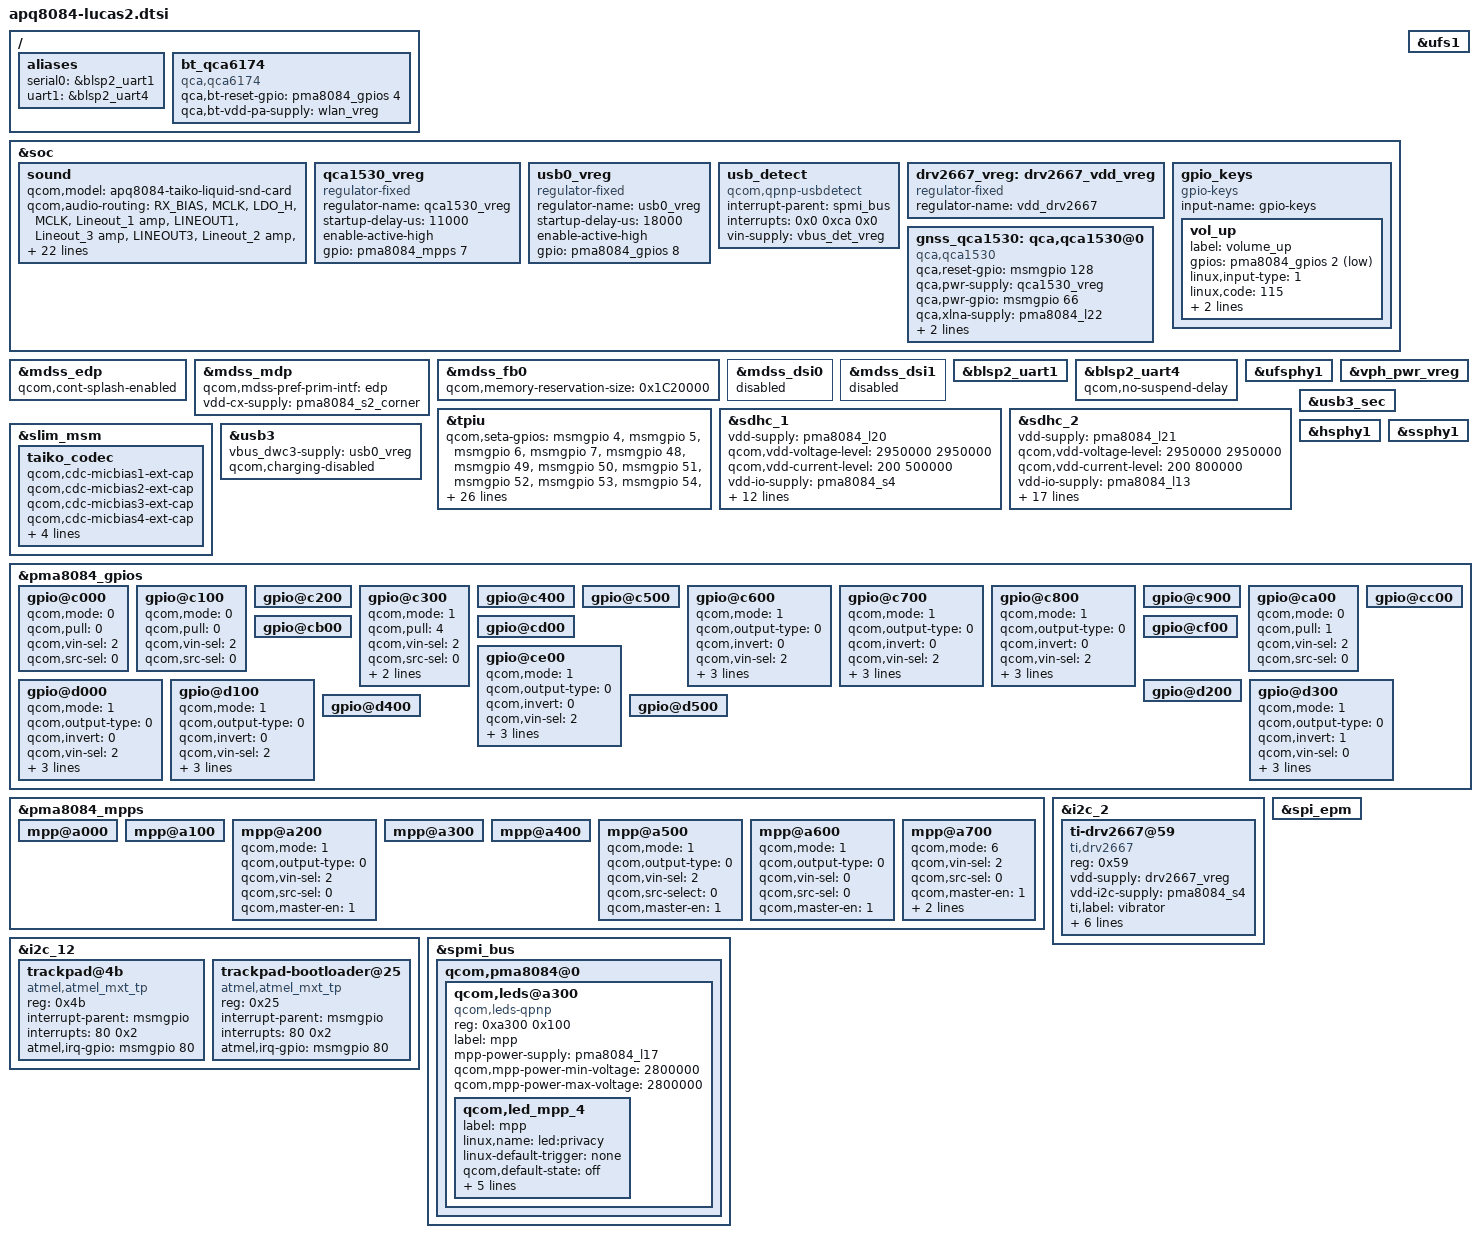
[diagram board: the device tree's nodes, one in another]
/* Copyright (c) 2014, The Linux Foundation. All rights reserved.
 *
 * This program is free software; you can redistribute it and/or modify
 * it under the terms of the GNU General Public License version 2 and
 * only version 2 as published by the Free Software Foundation.
 *
 * This program is distributed in the hope that it will be useful,
 * but WITHOUT ANY WARRANTY; without even the implied warranty of
 * MERCHANTABILITY or FITNESS FOR A PARTICULAR PURPOSE.  See the
 * GNU General Public License for more details.
 */

/ {
	aliases {
		serial0 = &blsp2_uart1;
		uart1 = &blsp2_uart4;
	};

	bt_qca6174 {
		compatible = "qca,qca6174";
		qca,bt-reset-gpio = <&pma8084_gpios 4 0>; /* BT_EN */
		qca,bt-vdd-pa-supply = <&wlan_vreg>;
	};
};

&soc {
	sound {
		qcom,model = "apq8084-taiko-liquid-snd-card";

		qcom,audio-routing =
			"RX_BIAS", "MCLK",
			"LDO_H", "MCLK",
			"Lineout_1 amp", "LINEOUT1",
			"Lineout_3 amp", "LINEOUT3",
			"Lineout_2 amp", "LINEOUT2",
			"Lineout_4 amp", "LINEOUT4",
			"SPK_ultrasound amp", "SPK_OUT",
			"AMIC1", "MIC BIAS3 External",
			"MIC BIAS3 External", "Analog Mic7",
			"AMIC2", "MIC BIAS2 External",
			"MIC BIAS2 External", "Headset Mic",
			"AMIC3", "MIC BIAS2 External",
			"MIC BIAS2 External", "ANCLeft Headset Mic",
			"AMIC4", "MIC BIAS2 External",
			"MIC BIAS2 External", "ANCRight Headset Mic",
			"DMIC1", "MIC BIAS4 External",
			"MIC BIAS4 External", "Digital Mic4",
			"DMIC2", "MIC BIAS3 External",
			"MIC BIAS3 External", "Digital Mic3",
			"DMIC3", "MIC BIAS1 External",
			"MIC BIAS1 External", "Digital Mic2",
			"DMIC4", "MIC BIAS1 External",
			"MIC BIAS1 External", "Digital Mic1",
			"DMIC5", "MIC BIAS3 External",
			"MIC BIAS3 External", "Digital Mic5",
			"DMIC6", "MIC BIAS3 External",
			"MIC BIAS3 External", "Digital Mic6";

			qcom,cdc-micbias2-headset-only;
			qcom,hdmi-audio-rx;
			qcom,ext-spk-amp-supply = <&hdmi_vreg>;
			qcom,ext-spk-amp-gpio = <&pma8084_mpps 6 0>;
	};

	qca1530_vreg: qca1530_vreg {
		compatible = "regulator-fixed";
		regulator-name = "qca1530_vreg";
		startup-delay-us = <11000>; /* the on time of SMB209AN */
		enable-active-high;
		gpio = <&pma8084_mpps 7 0>;
	};

	usb0_vreg: usb0_vreg {
		compatible = "regulator-fixed";
		regulator-name = "usb0_vreg";
		startup-delay-us = <18000>; /* the on time of TPD4S214 */
		enable-active-high;
		gpio = <&pma8084_gpios 8 0>;
	};

	usb_detect {
		compatible = "qcom,qpnp-usbdetect";
		interrupt-parent = <&spmi_bus>;
		interrupts = <0x0 0xca 0x0>;  /* PMA8084 GPIO 11 */
		interrupt-names = "vbus_det_irq";
		vin-supply = <&vbus_det_vreg>;
	};

	drv2667_vreg: drv2667_vdd_vreg {
		compatible = "regulator-fixed";
		regulator-name = "vdd_drv2667";
	};

	gpio_keys {
		compatible = "gpio-keys";
		input-name = "gpio-keys";

		vol_up {
			label = "volume_up";
			gpios = <&pma8084_gpios 2 0x1>;
			linux,input-type = <1>;
			linux,code = <115>;
			gpio-key,wakeup;
			debounce-interval = <15>;
		};
	};

	gnss_qca1530: qca,qca1530@0 {
		compatible = "qca,qca1530";
		qca,reset-gpio = <&msmgpio 128 0>;
		qca,pwr-supply = <&qca1530_vreg>;
		qca,pwr-gpio = <&msmgpio 66 0>;
		qca,xlna-supply = <&pma8084_l22>;
		qca,xlna-voltage-level = <3000000 3000000>;
		qca,xlna-current-level = <90000 100>;
	};

};

#include "apq8084-mdss-panels.dtsi"

&mdss_edp {
	qcom,cont-splash-enabled;
};

&mdss_mdp {
	qcom,mdss-pref-prim-intf = "edp";
	vdd-cx-supply = <&pma8084_s2_corner>;
};

&mdss_fb0 {
	qcom,memory-reservation-size = <0x1C20000>;
};

&mdss_dsi0 {
	status = "disabled";
};

&mdss_dsi1 {
	status = "disabled";
};

&blsp2_uart1 {
	status = "ok";
};

&blsp2_uart4 {
	qcom,no-suspend-delay;
	status = "ok";
};

/* CoreSight */
&tpiu {
	qcom,seta-gpios = <&msmgpio 4 0>,
			  <&msmgpio 5 0>,
			  <&msmgpio 6 0>,
			  <&msmgpio 7 0>,
			  <&msmgpio 48 0>,
			  <&msmgpio 49 0>,
			  <&msmgpio 50 0>,
			  <&msmgpio 51 0>,
			  <&msmgpio 52 0>,
			  <&msmgpio 53 0>,
			  <&msmgpio 54 0>,
			  <&msmgpio 55 0>,
			  <&msmgpio 56 0>,
			  <&msmgpio 57 0>,
			  <&msmgpio 63 0>,
			  <&msmgpio 64 0>,
			  <&msmgpio 75 0>,
			  <&msmgpio 122 0>;
	qcom,seta-gpios-func = <4 4 4 4 5 4 4 5 5 4 4 4 4 4 4 5 2 1>;
	qcom,seta-gpios-drv =  <7 7 7 7 7 7 7 7 7 7 7 7 7 7 7 7 7 7>;
	qcom,seta-gpios-pull = <0 0 0 0 0 0 0 0 0 0 0 0 0 0 0 0 0 0>;
	qcom,seta-gpios-dir =  <2 2 2 2 2 2 2 2 2 2 2 2 2 2 2 2 2 2>;

	qcom,setb-gpios = <&msmgpio 10 0>,
			  <&msmgpio 11 0>,
			  <&msmgpio 29 0>,
			  <&msmgpio 30 0>,
			  <&msmgpio 39 0>,
			  <&msmgpio 40 0>,
			  <&msmgpio 43 0>,
			  <&msmgpio 44 0>,
			  <&msmgpio 45 0>,
			  <&msmgpio 46 0>,
			  <&msmgpio 67 0>,
			  <&msmgpio 68 0>,
			  <&msmgpio 69 0>,
			  <&msmgpio 70 0>,
			  <&msmgpio 71 0>,
			  <&msmgpio 72 0>,
			  <&msmgpio 102 0>,
			  <&msmgpio 121 0>;
	qcom,setb-gpios-func = <4 4 5 4 4 4 4 4 4 4 3 3 2 4 3 3 2 1>;
	qcom,setb-gpios-drv =  <7 7 7 7 7 7 7 7 7 7 7 7 7 7 7 7 7 7>;
	qcom,setb-gpios-pull = <0 0 0 0 0 0 0 0 0 0 0 0 0 0 0 0 0 0>;
	qcom,setb-gpios-dir =  <2 2 2 2 2 2 2 2 2 2 2 2 2 2 2 2 2 2>;
};

&ufsphy1 {
	status = "ok";
};

&ufs1 {
	status = "ok";
};

&sdhc_1 {
	vdd-supply = <&pma8084_l20>;
	qcom,vdd-voltage-level = <2950000 2950000>;
	qcom,vdd-current-level = <200 500000>;

	vdd-io-supply = <&pma8084_s4>;
	qcom,vdd-io-always-on;
	qcom,vdd-io-voltage-level = <1800000 1800000>;
	qcom,vdd-io-current-level = <200 154000>;

	qcom,pad-pull-on = <0x0 0x3 0x3 0x1>; /* no-pull, pull-up, pull-up, pull-down */
	qcom,pad-pull-off = <0x0 0x3 0x3 0x1>; /* no-pull, pull-up, pull-up, pull-down */
	qcom,pad-drv-on = <0x7 0x4 0x4>; /* 16mA, 10mA, 10mA */
	qcom,pad-drv-off = <0x0 0x0 0x0>; /* 2mA, 2mA, 2mA */

	qcom,clk-rates = <400000 20000000 25000000 50000000 100000000 192000000 384000000>;
	qcom,nonremovable;
	qcom,bus-speed-mode = "HS400_1p8v", "HS200_1p8v", "DDR_1p8v";
	status = "ok";
};

&sdhc_2 {
	vdd-supply = <&pma8084_l21>;
	qcom,vdd-voltage-level = <2950000 2950000>;
	qcom,vdd-current-level = <200 800000>;

	vdd-io-supply = <&pma8084_l13>;
	qcom,vdd-io-voltage-level = <1800000 2950000>;
	qcom,vdd-io-current-level = <200 22000>;

	qcom,pad-pull-on = <0x0 0x3 0x3>; /* no-pull, pull-up, pull-up */
	qcom,pad-pull-off = <0x0 0x3 0x3>; /* no-pull, pull-up, pull-up */
	qcom,pad-drv-on = <0x7 0x4 0x4>; /* 16mA, 10mA, 10mA */
	qcom,pad-drv-off = <0x0 0x0 0x0>; /* 2mA, 2mA, 2mA */

	qcom,clk-rates = <400000 20000000 25000000 50000000 100000000 200000000>;
	qcom,bus-speed-mode = "SDR12", "SDR25", "SDR50", "DDR50", "SDR104";

	#address-cells = <0>;
	interrupt-parent = <&sdhc_2>;
	interrupts = <0 1 2>;
	#interrupt-cells = <1>;
	interrupt-map-mask = <0xffffffff>;
	interrupt-map = <0 &intc 0 125 0
			1 &intc 0 221 0
			2 &msmgpio 122 0x3>;
	interrupt-names = "hc_irq", "pwr_irq", "status_irq";
	cd-gpios = <&msmgpio 122 0x1>;
	wp-gpios = <&msmgpio 75 0x1>;

	status = "ok";
};

&vph_pwr_vreg {
	status = "ok";
};

&slim_msm {
	taiko_codec {
		qcom,cdc-micbias1-ext-cap;
		qcom,cdc-micbias2-ext-cap;
		qcom,cdc-micbias3-ext-cap;
		qcom,cdc-micbias4-ext-cap;

		/*
		 * Liquid has external spkrdrv supply. Give a dummy supply
		 * to make codec driver happy.
		 */
		cdc-vdd-spkdrv-supply = <&vph_pwr_vreg>;
		qcom,cdc-vdd-spkdrv-voltage = <0 0>;
		qcom,cdc-vdd-spkdrv-current = <0>;

		qcom,cdc-on-demand-supplies = "cdc-vdd-spkdrv";
	};
};

&usb3 {
	vbus_dwc3-supply = <&usb0_vreg>;
	qcom,charging-disabled;
};

&usb3_sec {
	status = "ok";
};

&hsphy1 {
	status = "ok";
};

&ssphy1 {
	status = "ok";
};

&pma8084_gpios {
	gpio@c000 { /* GPIO 1 */
		qcom,mode = <0>;
		qcom,pull = <0>;
		qcom,vin-sel = <2>;
		qcom,src-sel = <0>;
	};

	gpio@c100 { /* GPIO 2 */
		qcom,mode = <0>;
		qcom,pull = <0>;
		qcom,vin-sel = <2>;
		qcom,src-sel = <0>;
	};

	gpio@c200 { /* GPIO 3 */
	};

	gpio@c300 { /* GPIO 4 */
                qcom,mode = <1>;         /* Digital output*/
                qcom,pull = <4>;         /* Pulldown 10uA */
                qcom,vin-sel = <2>;      /* VIN2 */
                qcom,src-sel = <0>;      /* GPIO */
                qcom,invert = <0>;       /* Invert */
                qcom,master-en = <1>;    /* Enable GPIO */
	};

	gpio@c400 { /* GPIO 5 */
	};

	gpio@c500 { /* GPIO 6 */
	};

	gpio@c600 { /* GPIO 7 */
		/* Backlight PWM */
		qcom,mode = <1>;		/* Digital output */
		qcom,output-type = <0>;		/* CMOS logic */
		qcom,invert = <0>;		/* Do not invert the output */
		qcom,vin-sel = <2>;		/* PMA8084 S4 = 1.8 V */
		qcom,src-sel = <2>;		/* Special Function 1=LPG 3 */
		qcom,out-strength = <3>;	/* High drive strength */
		qcom,master-en = <1>;
	};

	gpio@c700 { /* GPIO 8 */
		qcom,mode = <1>;		/* Digital output */
		qcom,output-type = <0>;		/* CMOS logic */
		qcom,invert = <0>;		/* Output low initially */
		qcom,vin-sel = <2>;		/* VPH_PWR */
		qcom,src-sel = <0>;		/* Constant */
		qcom,out-strength = <1>;	/* Low */
		qcom,master-en = <1>;		/* Enable GPIO */
	};

	gpio@c800 { /* GPIO 9 */
		qcom,mode = <1>;		/* Digital output */
		qcom,output-type = <0>;		/* CMOS logic */
		qcom,invert = <0>;		/* Output low initially */
		qcom,vin-sel = <2>;		/* VPH_PWR */
		qcom,src-sel = <0>;		/* Constant */
		qcom,out-strength = <1>;	/* Low */
		qcom,master-en = <1>;		/* Enable GPIO */
	};

	gpio@c900 { /* GPIO 10 */
	};

	gpio@ca00 { /* GPIO 11 */
		/* VBUS interrupt */
		qcom,mode = <0>;
		qcom,pull = <1>;
		qcom,vin-sel = <2>;
		qcom,src-sel = <0>;
	};

	gpio@cb00 { /* GPIO 12 */
	};

	gpio@cc00 { /* GPIO 13 */
	};

	gpio@cd00 { /* GPIO 14 */
	};

	gpio@ce00 { /* GPIO 15 */
		qcom,mode = <1>;		/* Digital output */
		qcom,output-type = <0>;		/* CMOS logic */
		qcom,invert = <0>;		/* Output low initially */
		qcom,vin-sel = <2>;		/* VIN 2 */
		qcom,src-sel = <2>;		/* Function 1 */
		qcom,out-strength = <2>;	/* Medium */
		qcom,master-en = <1>;		/* Enable GPIO */
	};

	gpio@cf00 { /* GPIO 16 */
	};

	gpio@d000 { /* GPIO 17 */
		qcom,mode = <1>;		/* Digital output */
		qcom,output-type = <0>;		/* CMOS logic */
		qcom,invert = <0>;		/* Output low initially */
		qcom,vin-sel = <2>;		/* VIN 2 */
		qcom,src-sel = <3>;		/* Function 2 */
		qcom,out-strength = <2>;	/* Medium */
		qcom,master-en = <1>;		/* Enable GPIO */
	};

	gpio@d100 { /* GPIO 18 */
		qcom,mode = <1>;		/* Digital output */
		qcom,output-type = <0>;		/* CMOS logic */
		qcom,invert = <0>;		/* Output low initially */
		qcom,vin-sel = <2>;		/* VIN 2 */
		qcom,src-sel = <3>;		/* Function 2 */
		qcom,out-strength = <2>;	/* Medium */
		qcom,master-en = <1>;		/* Enable GPIO */
	};

	gpio@d200 { /* GPIO 19 */
	};

	gpio@d300 { /* GPIO 20 */
		qcom,mode = <1>;		/* Digital output */
		qcom,output-type = <0>;		/* CMOS logic */
		qcom,invert = <1>;		/* Output high */
		qcom,vin-sel = <0>;		/* VPH_PWR */
		qcom,src-sel = <0>;		/* Constant */
		qcom,out-strength = <1>;	/* Low */
		qcom,master-en = <1>;		/* Enable GPIO */
	};

	gpio@d400 { /* GPIO 21 */
	};

	gpio@d500 { /* GPIO 22 */
	};
};

&pma8084_mpps {
	mpp@a000 { /* MPP 1 */
	};

	mpp@a100 { /* MPP 2 */
	};

	mpp@a200 { /* MPP 3 */
		/* HDMI_5v_vreg regulator enable */
		qcom,mode = <1>;		/* Digital output */
		qcom,output-type = <0>;		/* CMOS logic */
		qcom,vin-sel = <2>;		/* VPH_PWR */
		qcom,src-sel = <0>;		/* Constant */
		qcom,master-en = <1>;		/* Enable GPIO */
	};

	mpp@a300 { /* MPP 4 */
	};

	mpp@a400 { /* MPP 5 */
	};

	mpp@a500 { /* MPP 6 */
		/* CLASS_D_EN speakers PA */
		qcom,mode = <1>;		/* DIG_OUT */
		qcom,output-type = <0>;		/* PNP_PIN_OUT_BUF_CMOS */
		qcom,vin-sel = <2>;		/* S3A 1.8v */
		qcom,src-select = <0>;		/* CONSTANT */
		qcom,master-en = <1>;		/* ENABLE MPP */
	};

	mpp@a600 { /* MPP 7 */
		/* QCA1350_vreg regulator enable */
		qcom,mode = <1>;		/* Digital output */
		qcom,output-type = <0>;		/* CMOS logic */
		qcom,vin-sel = <0>;		/* VPH_PWR */
		qcom,src-sel = <0>;		/* Constant */
		qcom,master-en = <1>;		/* Enable GPIO */
	};

	mpp@a700 { /* MPP 8 */
		qcom,mode = <6>; /* Sink mode */
		qcom,vin-sel =<2>; /* S4 1.8V */
		qcom,src-sel = <0>; /* Constant */
		qcom,master-en = <1>; /* Enabled */
		qcom,cs-out = <7>; /* 40 mA sink */
		qcom,invert = <1>; /* Invert = HIGH (always on) */
	};
};

&i2c_2 {
	ti-drv2667@59 {
		compatible = "ti,drv2667";
		reg = <0x59>;
		vdd-supply = <&drv2667_vreg>;
		vdd-i2c-supply = <&pma8084_s4>;
		ti,label = "vibrator";
		ti,gain = <2>;
		ti,idle-timeout-ms = <20>;
		ti,max-runtime-ms = <15000>;
		ti,mode = <2>;
		ti,wav-seq = [
			/* wave form id */
			01
			/* header size, start and stop bytes */
			05 80 06 00 09
			/* repeat, amp, freq, duration, envelope */
			01 ff 19 02 00];
	};
};

&i2c_12 {
	/* Only one of the following trackpads should be probed */
	trackpad@4b {
		reg=<0x4b>;
		compatible="atmel,atmel_mxt_tp";
                interrupt-parent = <&msmgpio>;
                interrupts = <80 0x2>;
		atmel,irq-gpio = <&msmgpio 80 0x00>;
	};
	trackpad-bootloader@25 {
		reg=<0x25>;
		compatible="atmel,atmel_mxt_tp";
                interrupt-parent = <&msmgpio>;
                interrupts = <80 0x2>;
		atmel,irq-gpio = <&msmgpio 80 0x00>;
	};
};

&spi_epm {
};

&spmi_bus {
	qcom,pma8084@0 {
		qcom,leds@a300 {
			compatible = "qcom,leds-qpnp";
			reg = <0xa300 0x100>;
			label = "mpp";
			status = "okay";
			mpp-power-supply = <&pma8084_l17>;
			qcom,mpp-power-min-voltage = <2800000>;
			qcom,mpp-power-max-voltage = <2800000>;
			qcom,led_mpp_4 {
				label = "mpp";
				linux,name = "led:privacy";
				linux-default-trigger = "none";
				qcom,default-state = "off";
				qcom,max-current = <40>;
				qcom,id = <6>;
				qcom,source-sel = <1>;
				qcom,mode-ctrl = <0x60>;
				qcom,mode = "manual";
			};
		};
	};
};
